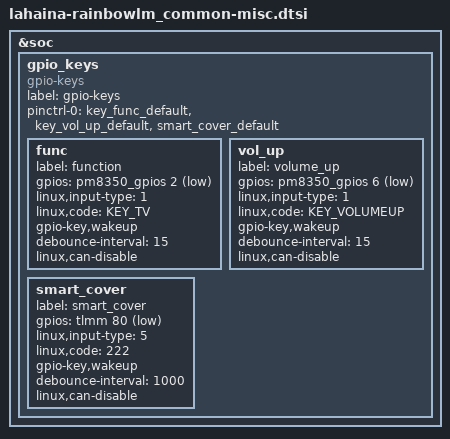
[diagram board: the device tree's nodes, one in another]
// SPDX-License-Identifier: GPL-2.0-only
/*
 * Copyright (c) 2018-2019, The Linux Foundation. All rights reserved.
 */
&soc {
	gpio_keys {
		compatible = "gpio-keys";
		label = "gpio-keys";

		pinctrl-names = "default";
		pinctrl-0 = <&key_func_default &key_vol_up_default &smart_cover_default>;

		func {
		 label = "function";
		 gpios = <&pm8350_gpios 2 GPIO_ACTIVE_LOW>;
		 linux,input-type = <1>;
		 linux,code = <KEY_TV>;
		 gpio-key,wakeup;
		 debounce-interval = <15>;
		 linux,can-disable;
		};

		vol_up {
			label = "volume_up";
			gpios = <&pm8350_gpios 6 GPIO_ACTIVE_LOW>;
			linux,input-type = <1>;
			linux,code = <KEY_VOLUMEUP>;
			gpio-key,wakeup;
			debounce-interval = <15>;
			linux,can-disable;
		};

		smart_cover {
			label = "smart_cover";
			gpios = <&tlmm 80 GPIO_ACTIVE_LOW>;
			linux,input-type = <5>;
			linux,code = <222>;
			gpio-key,wakeup;
			debounce-interval = <1000>;
			linux,can-disable;
		};
	};
};

